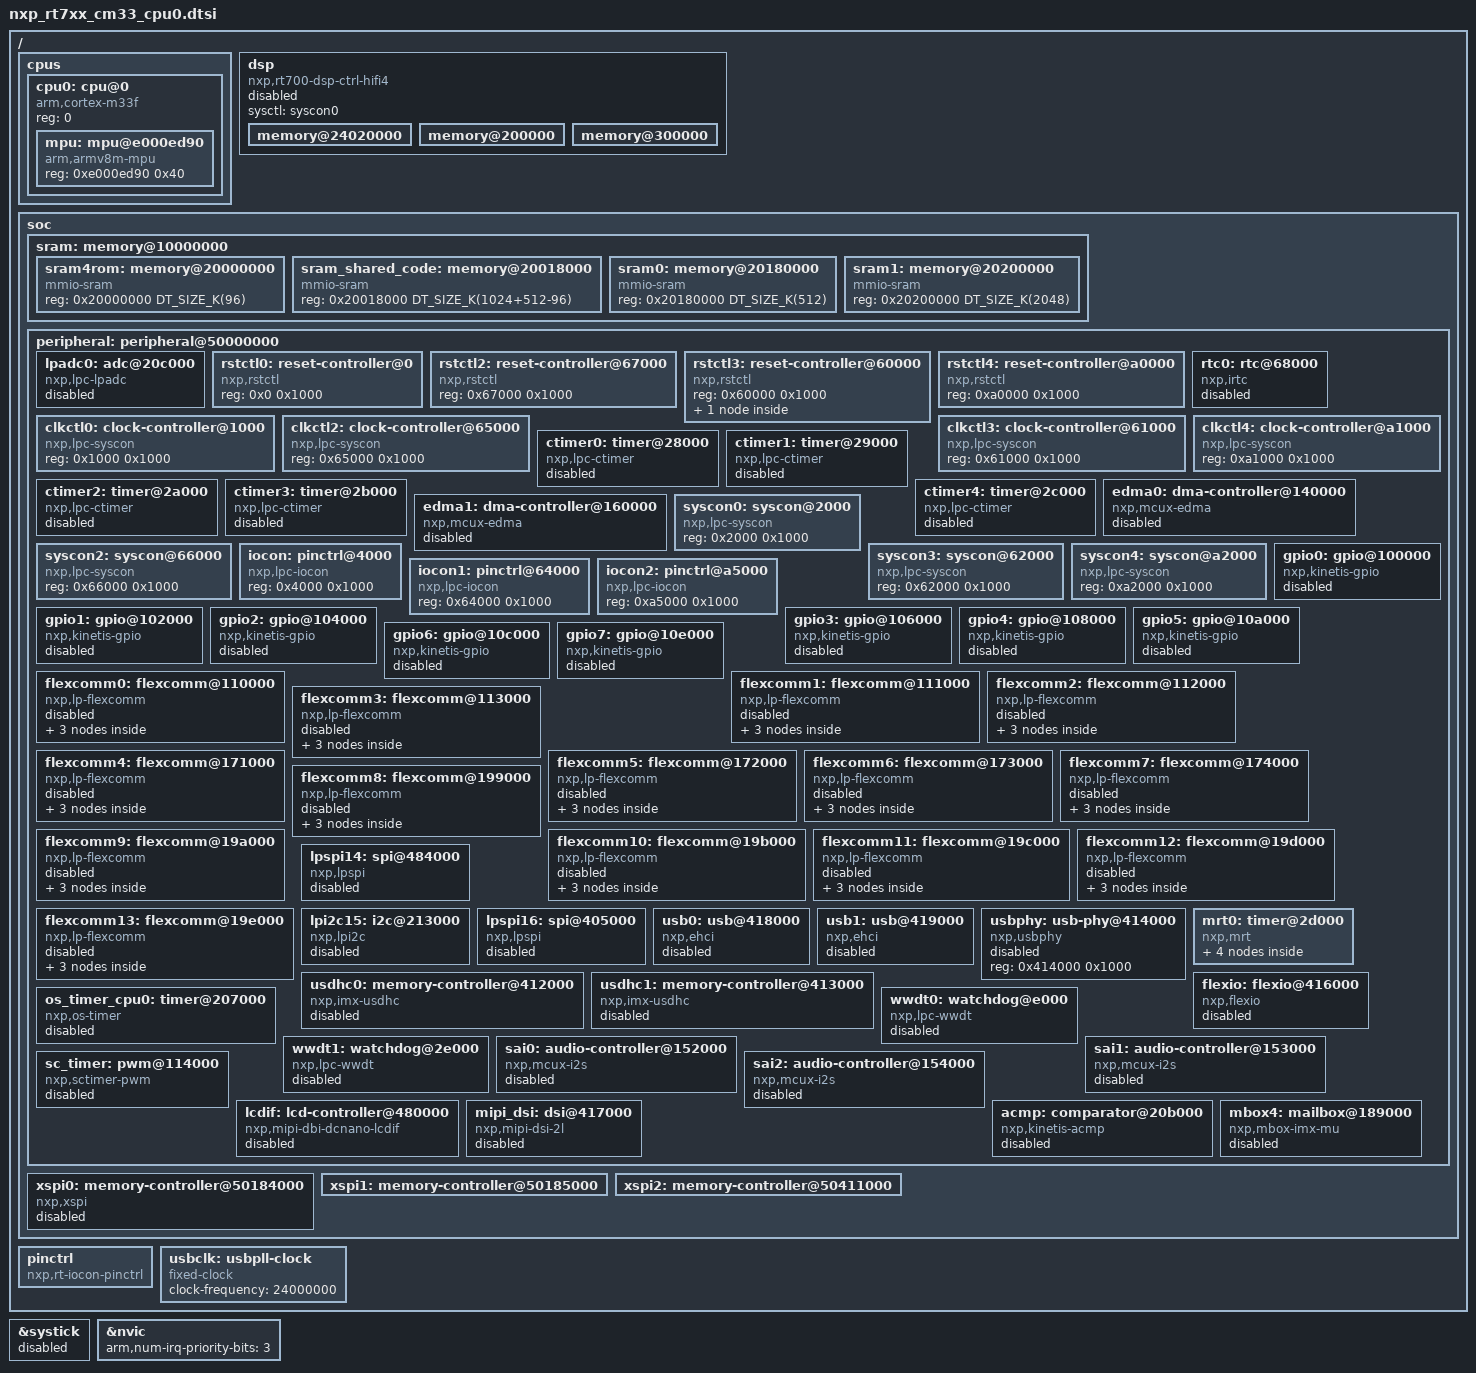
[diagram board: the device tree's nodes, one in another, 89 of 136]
/*
 * Copyright 2024-2025 NXP
 *
 * SPDX-License-Identifier: Apache-2.0
 */

#include <mem.h>
#include <arm/armv8-m.dtsi>
#include <zephyr/dt-bindings/adc/adc.h>
#include <zephyr/dt-bindings/clock/mcux_lpc_syscon_clock.h>
#include <zephyr/dt-bindings/gpio/gpio.h>
#include <zephyr/dt-bindings/mipi_dsi/mipi_dsi.h>
#include <zephyr/dt-bindings/memory-attr/memory-attr-arm.h>
#include <zephyr/dt-bindings/reset/nxp_syscon_reset_common.h>
#include <zephyr/dt-bindings/misc/nxp_rtxxx_dsp_ctrl.h>

/ {
	cpus {
		#address-cells = <1>;
		#size-cells = <0>;

		cpu0: cpu@0 {
			compatible = "arm,cortex-m33f";
			reg = <0>;
			#address-cells = <1>;
			#size-cells = <1>;

			mpu: mpu@e000ed90 {
				compatible = "arm,armv8m-mpu";
				reg = <0xe000ed90 0x40>;
			};
		};
	};

	dsp: dsp {
		#address-cells = <1>;
		#size-cells = <1>;

		compatible = "nxp,rt700-dsp-ctrl-hifi4";
		sysctl = <&syscon0>;

		status = "disabled";

		/* 1st 1 kiB of HiFi4's ITCM */
		memory@24020000 {
			reg = <0x24020000 DT_SIZE_K(1)>;
			type = <NXP_RTXXX_DSP_REGION_RESET>;
		};

		/* 1st half of reserved HiFi4 SRAM region (see below) */
		memory@200000 {
			reg = <0x200000 DT_SIZE_M(1)>;
			type = <NXP_RTXXX_DSP_REGION_TEXT>;
		};

		/* 2nd half of reserved HiFi4 SRAM region (see below) */
		memory@300000 {
			reg = <0x300000 DT_SIZE_M(1)>;
			type = <NXP_RTXXX_DSP_REGION_DATA>;
		};
	};

	soc {
		sram: memory@10000000 {
			ranges = <0x0 0x10000000 0x780000
				0x20000000 0x30000000 0x780000>;
		};

		peripheral: peripheral@50000000 {
			ranges = <0x0 0x50000000 0x10000000>;
		};

		xspi0: memory-controller@50184000 {
			reg = <0x50184000 0x1000>, <0x38000000 DT_SIZE_M(128)>;
		};

		xspi1: memory-controller@50185000 {
			reg = <0x50185000 0x1000>, <0x18000000 DT_SIZE_M(128)>;
		};

		xspi2: memory-controller@50411000 {
			reg = <0x50411000 0x1000>, <0x70000000 DT_SIZE_M(128)>;
		};

	};

	pinctrl: pinctrl {
		compatible = "nxp,rt-iocon-pinctrl";
	};

	/* USB PLL */
	usbclk: usbpll-clock {
		compatible = "fixed-clock";
		clock-frequency = <24000000>;
		#clock-cells = <0>;
	};
};


&sram {
	#address-cells = <1>;
	#size-cells = <1>;

	/* RT7XX SRAM partitions are shared between code and data. Boards can override
	 *  the reg properties of either sram0 or sram_code nodes to change the balance
	 *  of SRAM allocation.
	 *
	 * The SRAM region [0x000000-0x017FFF] is reserved for ROM bootloader execution.
	 * Can be reused after boot.
	 * The SRAM region [0x018000-0x17FFFF] is reserved for Non-cached shared memory
	 * or application data.
	 * The SRAM region [0x180000-0x1FFFFF] is reserved for CPU0 application, last
	 * 2MB non-cacheable data for NPU/GPU/Display etc.
	 * The SRAM region [0x200000-0x400000] is reserved for HiFi4 application.
	 */

	sram4rom: memory@20000000{
		compatible = "mmio-sram";
		reg = <0x20000000 DT_SIZE_K(96)>;
	};

	/* This partition is shared with code in RAM */
	sram_shared_code: memory@20018000{
		compatible = "mmio-sram";
		reg = <0x20018000 DT_SIZE_K(1024+512-96)>;
	};

	sram0: memory@20180000 {
		compatible = "mmio-sram";
		reg = <0x20180000 DT_SIZE_K(512)>;
	};

	sram1: memory@20200000 {
		compatible =  "mmio-sram";
		reg = <0x20200000 DT_SIZE_K(2048)>;
	};
};

&peripheral {
	#address-cells = <1>;
	#size-cells = <1>;
	/*
	 * Note that the offsets here are relative to the base address.
	 * The base addresses differ between non-secure (0x40000000)
	 * and secure modes (0x50000000).
	 */

	lpadc0: adc@20c000 {
		compatible = "nxp,lpc-lpadc";
		reg = <0x20c000 0x304>;
		interrupts = <15 0>;
		status = "disabled";
		clk-divider = <1>;
		clk-source = <0>;
		voltage-ref= <1>;
		calibration-average = <128>;
		power-level = <0>;
		offset-value-a = <10>;
		offset-value-b = <10>;
		#io-channel-cells = <1>;
		clocks = <&clkctl3 MCUX_LPADC1_CLK>;
	};

	rstctl0: reset-controller@0 {
		compatible = "nxp,rstctl";
		reg = <0x0 0x1000>;
		#reset-cells = <1>;
	};

	rstctl2: reset-controller@67000 {
		compatible = "nxp,rstctl";
		reg = <0x67000 0x1000>;
		#reset-cells = <1>;
	};

	rstctl3: reset-controller@60000 {
		compatible = "nxp,rstctl";
		reg = <0x60000 0x1000>;
		#reset-cells = <1>;
		#address-cells = <1>;
		#size-cells = <1>;

		sysrststat: hwinfo@60000 {
			compatible = "nxp,rstctl-hwinfo";
			reg = <0x60000 0x4>;
		};
	};

	rstctl4: reset-controller@a0000 {
		compatible = "nxp,rstctl";
		reg = <0xa0000 0x1000>;
		#reset-cells = <1>;
	};

	rtc0: rtc@68000 {
		compatible = "nxp,irtc";
		reg = <0x68000 0x1000>;
		interrupts = <26 0>, <27 0>;
		clock-frequency = <32768>;
		prescaler = <1>;
		alarms-count = <1>;
		status = "disabled";
	};

	clkctl0: clock-controller@1000 {
		compatible = "nxp,lpc-syscon";
		reg = <0x1000 0x1000>;
		#clock-cells = <1>;
	};

	clkctl2: clock-controller@65000 {
		compatible = "nxp,lpc-syscon";
		reg = <0x65000 0x1000>;
		#clock-cells = <1>;
	};

	clkctl3: clock-controller@61000 {
		compatible = "nxp,lpc-syscon";
		reg = <0x61000 0x1000>;
		#clock-cells = <1>;
	};

	clkctl4: clock-controller@a1000 {
		compatible = "nxp,lpc-syscon";
		reg = <0xa1000 0x1000>;
		#clock-cells = <1>;
	};

	ctimer0: timer@28000 {
		compatible = "nxp,lpc-ctimer";
		reg = <0x28000 0x1000>;
		interrupts = <3 0>;
		status = "disabled";
		clk-source = <1>;
		clocks = <&clkctl0 MCUX_CTIMER0_CLK>;
		mode = <0>;
		input = <0>;
		prescale = <0>;
	};

	ctimer1: timer@29000 {
		compatible = "nxp,lpc-ctimer";
		reg = <0x29000 0x1000>;
		interrupts = <4 0>;
		status = "disabled";
		clk-source = <1>;
		clocks = <&clkctl0 MCUX_CTIMER1_CLK>;
		mode = <0>;
		input = <0>;
		prescale = <0>;
	};

	ctimer2: timer@2a000 {
		compatible = "nxp,lpc-ctimer";
		reg = <0x2a000 0x1000>;
		interrupts = <32 0>;
		status = "disabled";
		clk-source = <1>;
		clocks = <&clkctl0 MCUX_CTIMER2_CLK>;
		mode = <0>;
		input = <0>;
		prescale = <0>;
	};

	ctimer3: timer@2b000 {
		compatible = "nxp,lpc-ctimer";
		reg = <0x2b000 0x1000>;
		interrupts = <6 0>;
		status = "disabled";
		clk-source = <1>;
		clocks = <&clkctl0 MCUX_CTIMER3_CLK>;
		mode = <0>;
		input = <0>;
		prescale = <0>;
	};

	ctimer4: timer@2c000 {
		compatible = "nxp,lpc-ctimer";
		reg = <0x2c000 0x1000>;
		interrupts = <33 0>;
		status = "disabled";
		clk-source = <1>;
		clocks = <&clkctl0 MCUX_CTIMER4_CLK>;
		mode = <0>;
		input = <0>;
		prescale = <0>;
	};

	edma0: dma-controller@140000 {
		#dma-cells = <2>;
		compatible = "nxp,mcux-edma";
		nxp,version = <4>;
		dma-channels = <16>;
		dma-requests = <105>;
		reg = <0x140000 0x1000>;
		interrupts = <59 0>, <60 0>, <61 0>, <62 0>,
			<63 0>, <64 0>, <65 0>, <66 0>,
			<67 0>, <68 0>, <69 0>, <70 0>,
			<71 0>, <72 0>, <73 0>, <74 0>;
		no-error-irq;
		status = "disabled";
	};

	edma1: dma-controller@160000 {
		#dma-cells = <2>;
		compatible = "nxp,mcux-edma";
		nxp,version = <4>;
		dma-channels = <16>;
		dma-requests = <105>;
		reg = <0x160000 0x1000>;
		interrupts = <75 0>, <76 0>, <77 0>, <78 0>,
			<79 0>, <80 0>, <81 0>, <82 0>,
			<83 0>, <84 0>, <85 0>, <86 0>,
			<87 0>, <88 0>, <89 0>, <90 0>;
		no-error-irq;
		status = "disabled";
	};

	syscon0: syscon@2000 {
		compatible = "nxp,lpc-syscon";
		reg = <0x2000 0x1000>;
		#clock-cells = <1>;
		#pinmux-cells = <2>;
	};

	syscon2: syscon@66000 {
		compatible = "nxp,lpc-syscon";
		reg = <0x66000 0x1000>;
		#clock-cells = <1>;
	};

	syscon3: syscon@62000 {
		compatible = "nxp,lpc-syscon";
		reg = <0x62000 0x1000>;
		#clock-cells = <1>;
	};

	syscon4: syscon@a2000 {
		compatible = "nxp,lpc-syscon";
		reg = <0xa2000 0x1000>;
		#clock-cells = <1>;
	};

	iocon: pinctrl@4000 {
		compatible = "nxp,lpc-iocon";
		reg = <0x4000 0x1000>;
		status = "okay";
	};

	iocon1: pinctrl@64000 {
		compatible = "nxp,lpc-iocon";
		reg = <0x64000 0x1000>;
		status = "okay";
	};

	iocon2: pinctrl@a5000 {
		compatible = "nxp,lpc-iocon";
		reg = <0xa5000 0x1000>;
		status = "okay";
	};

	gpio0: gpio@100000 {
		compatible = "nxp,kinetis-gpio";
		status = "disabled";
		reg = <0x100000 0x1000>;
		interrupts = <91 0>,<92 0>;
		gpio-controller;
		#gpio-cells = <2>;
		nxp,kinetis-port = <&gpio0>;
	};

	gpio1: gpio@102000 {
		compatible = "nxp,kinetis-gpio";
		status = "disabled";
		reg = <0x102000 0x1000>;
		interrupts = <93 0>,<94 0>;
		gpio-controller;
		#gpio-cells = <2>;
		nxp,kinetis-port = <&gpio1>;
	};

	gpio2: gpio@104000 {
		compatible = "nxp,kinetis-gpio";
		status = "disabled";
		reg = <0x104000 0x1000>;
		interrupts = <95 0>,<96 0>;
		gpio-controller;
		#gpio-cells = <2>;
		nxp,kinetis-port = <&gpio2>;
	};

	gpio3: gpio@106000 {
		compatible = "nxp,kinetis-gpio";
		status = "disabled";
		reg = <0x106000 0x1000>;
		interrupts = <97 0>,<98 0>;
		gpio-controller;
		#gpio-cells = <2>;
		nxp,kinetis-port = <&gpio3>;
	};

	gpio4: gpio@108000 {
		compatible = "nxp,kinetis-gpio";
		status = "disabled";
		reg = <0x108000 0x1000>;
		interrupts = <99 0>,<100 0>;
		gpio-controller;
		#gpio-cells = <2>;
		nxp,kinetis-port = <&gpio4>;
	};

	gpio5: gpio@10a000 {
		compatible = "nxp,kinetis-gpio";
		status = "disabled";
		reg = <0x10a000 0x1000>;
		interrupts = <101 0>,<102 0>;
		gpio-controller;
		#gpio-cells = <2>;
		nxp,kinetis-port = <&gpio5>;
	};

	gpio6: gpio@10c000 {
		compatible = "nxp,kinetis-gpio";
		status = "disabled";
		reg = <0x10c000 0x1000>;
		interrupts = <103 0>,<104 0>;
		gpio-controller;
		#gpio-cells = <2>;
		nxp,kinetis-port = <&gpio6>;
	};

	gpio7: gpio@10e000 {
		compatible = "nxp,kinetis-gpio";
		status = "disabled";
		reg = <0x10e000 0x1000>;
		interrupts = <105 0>,<106 0>;
		gpio-controller;
		#gpio-cells = <2>;
		nxp,kinetis-port = <&gpio7>;
	};

	flexcomm0: flexcomm@110000 {
		compatible = "nxp,lp-flexcomm";
		reg = <0x110000 0x1000>;
		interrupts = <7 0>;
		status = "disabled";

		/* Empty ranges property implies parent and child address space is identical */
		ranges = <>;
		#address-cells = <1>;
		#size-cells = <1>;

		flexcomm0_lpuart0: serial@110000 {
			compatible = "nxp,lpuart";
			reg = <0x110000 0x1000>;
			clocks = <&clkctl0 MCUX_FLEXCOMM0_CLK>;
			status = "disabled";
		};

		flexcomm0_lpspi0: spi@110000 {
			compatible = "nxp,lpspi";
			reg = <0x110000 0x1000>;
			clocks = <&clkctl0 MCUX_FLEXCOMM0_CLK>;
			#address-cells = <1>;
			#size-cells = <0>;
			tx-fifo-size = <8>;
			rx-fifo-size = <8>;
			status = "disabled";
		};

		flexcomm0_lpi2c0: i2c@110800 {
			compatible = "nxp,lpi2c";
			reg = <0x110800 0x1000>;
			clocks = <&clkctl0 MCUX_FLEXCOMM0_CLK>;
			#address-cells = <1>;
			#size-cells = <0>;
			status = "disabled";
		};
	};

	flexcomm1: flexcomm@111000 {
		compatible = "nxp,lp-flexcomm";
		reg = <0x111000 0x1000>;
		interrupts = <8 0>;
		status = "disabled";

		/* Empty ranges property implies parent and child address space is identical */
		ranges = <>;
		#address-cells = <1>;
		#size-cells = <1>;

		flexcomm1_lpuart1: serial@111000 {
			compatible = "nxp,lpuart";
			reg = <0x111000 0x1000>;
			clocks = <&clkctl0 MCUX_FLEXCOMM1_CLK>;
			status = "disabled";
		};

		flexcomm1_lpspi1: spi@111000 {
			compatible = "nxp,lpspi";
			reg = <0x111000 0x1000>;
			clocks = <&clkctl0 MCUX_FLEXCOMM1_CLK>;
			#address-cells = <1>;
			#size-cells = <0>;
			tx-fifo-size = <8>;
			rx-fifo-size = <8>;
			status = "disabled";
		};

		flexcomm1_lpi2c1: i2c@111800 {
			compatible = "nxp,lpi2c";
			reg = <0x111800 0x1000>;
			clocks = <&clkctl0 MCUX_FLEXCOMM1_CLK>;
			#address-cells = <1>;
			#size-cells = <0>;
			status = "disabled";
		};
	};

	flexcomm2: flexcomm@112000 {
		compatible = "nxp,lp-flexcomm";
		reg = <0x112000 0x1000>;
		interrupts = <9 0>;
		status = "disabled";

		/* Empty ranges property implies parent and child address space is identical */
		ranges = <>;
		#address-cells = <1>;
		#size-cells = <1>;

		flexcomm2_lpuart2: serial@112000 {
			compatible = "nxp,lpuart";
			reg = <0x112000 0x1000>;
			clocks = <&clkctl0 MCUX_FLEXCOMM2_CLK>;
			status = "disabled";
		};

		flexcomm2_lpspi2: spi@112000 {
			compatible = "nxp,lpspi";
			reg = <0x112000 0x1000>;
			clocks = <&clkctl0 MCUX_FLEXCOMM2_CLK>;
			#address-cells = <1>;
			#size-cells = <0>;
			tx-fifo-size = <8>;
			rx-fifo-size = <8>;
			status = "disabled";
		};

		flexcomm2_lpi2c2: i2c@112800 {
			compatible = "nxp,lpi2c";
			reg = <0x112800 0x1000>;
			clocks = <&clkctl0 MCUX_FLEXCOMM2_CLK>;
			#address-cells = <1>;
			#size-cells = <0>;
			status = "disabled";
		};
	};

	flexcomm3: flexcomm@113000 {
		compatible = "nxp,lp-flexcomm";
		reg = <0x113000 0x1000>;
		interrupts = <10 0>;
		status = "disabled";

		/* Empty ranges property implies parent and child address space is identical */
		ranges = <>;
		#address-cells = <1>;
		#size-cells = <1>;

		flexcomm3_lpuart3: serial@113000 {
			compatible = "nxp,lpuart";
			reg = <0x113000 0x1000>;
			clocks = <&clkctl0 MCUX_FLEXCOMM3_CLK>;
			status = "disabled";
		};

		flexcomm3_lpspi3: spi@113000 {
			compatible = "nxp,lpspi";
			reg = <0x113000 0x1000>;
			clocks = <&clkctl0 MCUX_FLEXCOMM3_CLK>;
			#address-cells = <1>;
			#size-cells = <0>;
			tx-fifo-size = <8>;
			rx-fifo-size = <8>;
			status = "disabled";
		};

		flexcomm3_lpi2c3: i2c@113800 {
			compatible = "nxp,lpi2c";
			reg = <0x113800 0x1000>;
			clocks = <&clkctl0 MCUX_FLEXCOMM3_CLK>;
			#address-cells = <1>;
			#size-cells = <0>;
			status = "disabled";
		};
	};

	flexcomm4: flexcomm@171000 {
		compatible = "nxp,lp-flexcomm";
		reg = <0x171000 0x1000>;
		interrupts = <11 0>;
		status = "disabled";

		/* Empty ranges property implies parent and child address space is identical */
		ranges = <>;
		#address-cells = <1>;
		#size-cells = <1>;

		flexcomm4_lpuart4: serial@171000 {
			compatible = "nxp,lpuart";
			reg = <0x171000 0x1000>;
			clocks = <&clkctl0 MCUX_FLEXCOMM4_CLK>;
			status = "disabled";
		};

		flexcomm4_lpspi4: spi@171000 {
			compatible = "nxp,lpspi";
			reg = <0x171000 0x1000>;
			clocks = <&clkctl0 MCUX_FLEXCOMM4_CLK>;
			#address-cells = <1>;
			#size-cells = <0>;
			tx-fifo-size = <8>;
			rx-fifo-size = <8>;
			status = "disabled";
		};

		flexcomm4_lpi2c4: i2c@171800 {
			compatible = "nxp,lpi2c";
			reg = <0x171800 0x1000>;
			clocks = <&clkctl0 MCUX_FLEXCOMM4_CLK>;
			#address-cells = <1>;
			#size-cells = <0>;
			status = "disabled";
		};
	};

	flexcomm5: flexcomm@172000 {
		compatible = "nxp,lp-flexcomm";
		reg = <0x172000 0x1000>;
		interrupts = <12 0>;
		status = "disabled";

		/* Empty ranges property implies parent and child address space is identical */
		ranges = <>;
		#address-cells = <1>;
		#size-cells = <1>;

		flexcomm5_lpuart5: serial@172000 {
			compatible = "nxp,lpuart";
			reg = <0x172000 0x1000>;
			clocks = <&clkctl0 MCUX_FLEXCOMM5_CLK>;
			status = "disabled";
		};

		flexcomm5_lpspi5: spi@172000 {
			compatible = "nxp,lpspi";
			reg = <0x172000 0x1000>;
			clocks = <&clkctl0 MCUX_FLEXCOMM5_CLK>;
			#address-cells = <1>;
			#size-cells = <0>;
			tx-fifo-size = <8>;
			rx-fifo-size = <8>;
			status = "disabled";
		};

		flexcomm5_lpi2c5: i2c@172800 {
			compatible = "nxp,lpi2c";
			reg = <0x172800 0x1000>;
			clocks = <&clkctl0 MCUX_FLEXCOMM5_CLK>;
			#address-cells = <1>;
			#size-cells = <0>;
			status = "disabled";
		};
	};

	flexcomm6: flexcomm@173000 {
		compatible = "nxp,lp-flexcomm";
		reg = <0x173000 0x1000>;
		interrupts = <35 0>;
		status = "disabled";

		/* Empty ranges property implies parent and child address space is identical */
		ranges = <>;
		#address-cells = <1>;
		#size-cells = <1>;

		flexcomm6_lpuart6: serial@173000 {
			compatible = "nxp,lpuart";
			reg = <0x173000 0x1000>;
			clocks = <&clkctl0 MCUX_FLEXCOMM6_CLK>;
			status = "disabled";
		};

		flexcomm6_lpspi6: spi@173000 {
			compatible = "nxp,lpspi";
			reg = <0x173000 0x1000>;
			clocks = <&clkctl0 MCUX_FLEXCOMM6_CLK>;
			#address-cells = <1>;
			#size-cells = <0>;
			tx-fifo-size = <8>;
			rx-fifo-size = <8>;
			status = "disabled";
		};

		flexcomm6_lpi2c6: i2c@173800 {
			compatible = "nxp,lpi2c";
			reg = <0x173800 0x1000>;
			clocks = <&clkctl0 MCUX_FLEXCOMM6_CLK>;
			#address-cells = <1>;
			#size-cells = <0>;
			status = "disabled";
		};
	};

	flexcomm7: flexcomm@174000 {
		compatible = "nxp,lp-flexcomm";
		reg = <0x174000 0x1000>;
		interrupts = <36 0>;
		status = "disabled";

		/* Empty ranges property implies parent and child address space is identical */
		ranges = <>;
		#address-cells = <1>;
		#size-cells = <1>;

		flexcomm7_lpuart7: serial@174000 {
			compatible = "nxp,lpuart";
			reg = <0x174000 0x1000>;
			clocks = <&clkctl0 MCUX_FLEXCOMM7_CLK>;
			status = "disabled";
		};

		flexcomm7_lpspi7: spi@174000 {
			compatible = "nxp,lpspi";
			reg = <0x174000 0x1000>;
			clocks = <&clkctl0 MCUX_FLEXCOMM7_CLK>;
			#address-cells = <1>;
			#size-cells = <0>;
			tx-fifo-size = <8>;
			rx-fifo-size = <8>;
			status = "disabled";
		};

		flexcomm7_lpi2c7: i2c@174800 {
			compatible = "nxp,lpi2c";
			reg = <0x174800 0x1000>;
			clocks = <&clkctl0 MCUX_FLEXCOMM7_CLK>;
			#address-cells = <1>;
			#size-cells = <0>;
			status = "disabled";
		};
	};

	flexcomm8: flexcomm@199000 {
		compatible = "nxp,lp-flexcomm";
		reg = <0x199000 0x1000>;
		interrupts = <47 0>;
		status = "disabled";

		/* Empty ranges property implies parent and child address space is identical */
		ranges = <>;
		#address-cells = <1>;
		#size-cells = <1>;

		flexcomm8_lpuart8: serial@199000 {
			compatible = "nxp,lpuart";
			reg = <0x199000 0x1000>;
			clocks = <&clkctl0 MCUX_FLEXCOMM8_CLK>;
			status = "disabled";
		};

		flexcomm8_lpspi8: spi@199000 {
			compatible = "nxp,lpspi";
			reg = <0x199000 0x1000>;
			clocks = <&clkctl0 MCUX_FLEXCOMM8_CLK>;
			#address-cells = <1>;
			#size-cells = <0>;
			tx-fifo-size = <8>;
			rx-fifo-size = <8>;
			status = "disabled";
		};

		flexcomm8_lpi2c8: i2c@199800 {
			compatible = "nxp,lpi2c";
			reg = <0x199800 0x1000>;
			clocks = <&clkctl0 MCUX_FLEXCOMM8_CLK>;
			#address-cells = <1>;
			#size-cells = <0>;
			status = "disabled";
		};
	};

	flexcomm9: flexcomm@19a000 {
		compatible = "nxp,lp-flexcomm";
		reg = <0x19a000 0x1000>;
		interrupts = <48 0>;
		status = "disabled";

		/* Empty ranges property implies parent and child address space is identical */
		ranges = <>;
		#address-cells = <1>;
		#size-cells = <1>;

		flexcomm9_lpuart9: serial@19a000 {
			compatible = "nxp,lpuart";
			reg = <0x19a000 0x1000>;
			clocks = <&clkctl0 MCUX_FLEXCOMM9_CLK>;
			status = "disabled";
		};

		flexcomm9_lpspi9: spi@19a000 {
			compatible = "nxp,lpspi";
			reg = <0x19a000 0x1000>;
			clocks = <&clkctl0 MCUX_FLEXCOMM9_CLK>;
			#address-cells = <1>;
			#size-cells = <0>;
			tx-fifo-size = <8>;
			rx-fifo-size = <8>;
			status = "disabled";
		};

		flexcomm9_lpi2c9: i2c@19a800 {
			compatible = "nxp,lpi2c";
			reg = <0x19a800 0x1000>;
			clocks = <&clkctl0 MCUX_FLEXCOMM9_CLK>;
			#address-cells = <1>;
			#size-cells = <0>;
			status = "disabled";
		};
	};

	flexcomm10: flexcomm@19b000 {
		compatible = "nxp,lp-flexcomm";
		reg = <0x19b000 0x1000>;
		interrupts = <49 0>;
		status = "disabled";

		/* Empty ranges property implies parent and child address space is identical */
		ranges = <>;
		#address-cells = <1>;
		#size-cells = <1>;

		flexcomm10_lpuart10: serial@19b000 {
			compatible = "nxp,lpuart";
			reg = <0x19b000 0x1000>;
			clocks = <&clkctl0 MCUX_FLEXCOMM10_CLK>;
			status = "disabled";
		};

		flexcomm10_lpspi10: spi@19b000 {
			compatible = "nxp,lpspi";
			reg = <0x19b000 0x1000>;
			clocks = <&clkctl0 MCUX_FLEXCOMM10_CLK>;
			#address-cells = <1>;
			#size-cells = <0>;
			tx-fifo-size = <8>;
			rx-fifo-size = <8>;
			status = "disabled";
		};

		flexcomm10_lpi2c10: i2c@19b800 {
			compatible = "nxp,lpi2c";
			reg = <0x19b800 0x1000>;
			clocks = <&clkctl0 MCUX_FLEXCOMM10_CLK>;
			#address-cells = <1>;
			#size-cells = <0>;
			status = "disabled";
		};
	};

	flexcomm11: flexcomm@19c000 {
		compatible = "nxp,lp-flexcomm";
		reg = <0x19c000 0x1000>;
		interrupts = <50 0>;
		status = "disabled";

		/* Empty ranges property implies parent and child address space is identical */
		ranges = <>;
		#address-cells = <1>;
		#size-cells = <1>;

		flexcomm11_lpuart11: serial@19c000 {
			compatible = "nxp,lpuart";
			reg = <0x19c000 0x1000>;
			clocks = <&clkctl0 MCUX_FLEXCOMM11_CLK>;
			status = "disabled";
		};

		flexcomm11_lpspi11: spi@19c000 {
			compatible = "nxp,lpspi";
			reg = <0x19c000 0x1000>;
			clocks = <&clkctl0 MCUX_FLEXCOMM11_CLK>;
			#address-cells = <1>;
			#size-cells = <0>;
			tx-fifo-size = <8>;
			rx-fifo-size = <8>;
			status = "disabled";
		};

		flexcomm11_lpi2c11: i2c@19c800 {
			compatible = "nxp,lpi2c";
			reg = <0x19c800 0x1000>;
			clocks = <&clkctl0 MCUX_FLEXCOMM11_CLK>;
			#address-cells = <1>;
			#size-cells = <0>;
			status = "disabled";
		};
	};

	flexcomm12: flexcomm@19d000 {
		compatible = "nxp,lp-flexcomm";
		reg = <0x19d000 0x1000>;
		interrupts = <51 0>;
		status = "disabled";

		/* Empty ranges property implies parent and child address space is identical */
		ranges = <>;
		#address-cells = <1>;
		#size-cells = <1>;

		flexcomm12_lpuart12: serial@19d000 {
			compatible = "nxp,lpuart";
			reg = <0x19d000 0x1000>;
			clocks = <&clkctl0 MCUX_FLEXCOMM12_CLK>;
			status = "disabled";
		};

		flexcomm12_lpspi12: spi@19d000 {
			compatible = "nxp,lpspi";
			reg = <0x19d000 0x1000>;
			clocks = <&clkctl0 MCUX_FLEXCOMM12_CLK>;
			#address-cells = <1>;
			#size-cells = <0>;
			tx-fifo-size = <8>;
			rx-fifo-size = <8>;
			status = "disabled";
		};

		flexcomm12_lpi2c12: i2c@19d800 {
			compatible = "nxp,lpi2c";
			reg = <0x19d800 0x1000>;
			clocks = <&clkctl0 MCUX_FLEXCOMM12_CLK>;
			#address-cells = <1>;
			#size-cells = <0>;
			status = "disabled";
		};
	};

	flexcomm13: flexcomm@19e000 {
		compatible = "nxp,lp-flexcomm";
		reg = <0x19e000 0x1000>;
		interrupts = <52 0>;
		status = "disabled";

		/* Empty ranges property implies parent and child address space is identical */
		ranges = <>;
		#address-cells = <1>;
		#size-cells = <1>;

		flexcomm13_lpuart13: serial@19e000 {
			compatible = "nxp,lpuart";
			reg = <0x19e000 0x1000>;
			clocks = <&clkctl0 MCUX_FLEXCOMM13_CLK>;
			status = "disabled";
		};

		flexcomm13_lpspi13: spi@19e000 {
			compatible = "nxp,lpspi";
			reg = <0x19e000 0x1000>;
			clocks = <&clkctl0 MCUX_FLEXCOMM13_CLK>;
			#address-cells = <1>;
			#size-cells = <0>;
			tx-fifo-size = <8>;
			rx-fifo-size = <8>;
			status = "disabled";
		};

		flexcomm13_lpi2c13: i2c@19e800 {
			compatible = "nxp,lpi2c";
			reg = <0x19e800 0x1000>;
			clocks = <&clkctl0 MCUX_FLEXCOMM13_CLK>;
			#address-cells = <1>;
			#size-cells = <0>;
			status = "disabled";
		};
	};

	/* LPFlexcomm14/16 only support LPSPI function  */
	lpspi14: spi@484000 {
		compatible = "nxp,lpspi";
		reg = <0x484000 0x1000>;
		interrupts = <13 0>;
		clocks = <&clkctl4 MCUX_LPSPI14_CLK>;
		#address-cells = <1>;
		#size-cells = <0>;
		tx-fifo-size = <8>;
		rx-fifo-size = <8>;
		status = "disabled";
	};


	/* LPFlexcomm15 only support LPI2C function. */
	lpi2c15: i2c@213000 {
		compatible = "nxp,lpi2c";
		reg = <0x213000 0x1000>;
		interrupts = <14 0>;
		#address-cells = <1>;
		#size-cells = <0>;
		clocks = <&clkctl4 MCUX_LPI2C15_CLK>;
		status = "disabled";
	};

	/* LPFlexcomm14/16 only support LPSPI function  */
	lpspi16: spi@405000 {
		compatible = "nxp,lpspi";
		reg = <0x405000 0x1000>;
		interrupts = <53 0>;
		clocks = <&clkctl4 MCUX_LPSPI16_CLK>;
		#address-cells = <1>;
		#size-cells = <0>;
		tx-fifo-size = <8>;
		rx-fifo-size = <8>;
		status = "disabled";
	};

	usb0: usb@418000 {
		compatible = "nxp,ehci";
		reg = <0x418000 0x1000>;
		interrupts = <40 0>;
		interrupt-names = "usb_otg";
		clocks = <&usbclk>;
		num-bidir-endpoints = <8>;
		status = "disabled";
	};

	usb1: usb@419000 {
		compatible = "nxp,ehci";
		reg = <0x419000 0x1000>;
		interrupts = <41 0>;
		interrupt-names = "usb_otg";
		clocks = <&usbclk>;
		num-bidir-endpoints = <8>;
		status = "disabled";
	};

	usbphy: usb-phy@414000 {
		compatible = "nxp,usbphy";
		reg = <0x414000 0x1000>;
		status = "disabled";
	};

	usdhc0: memory-controller@412000 {
		compatible = "nxp,imx-usdhc";
		reg = <0x412000 0x1000>;
		status = "disabled";
		interrupts = <37 0>;
		clocks = <&clkctl4 MCUX_USDHC1_CLK>;
		max-current-330 = <1020>;
		max-current-180 = <1020>;
		max-bus-freq = <208000000>;
		min-bus-freq = <400000>;
	};

	usdhc1: memory-controller@413000 {
		compatible = "nxp,imx-usdhc";
		reg = <0x413000 0x1000>;
		status = "disabled";
		interrupts = <38 0>;
		clocks = <&clkctl4 MCUX_USDHC2_CLK>;
		max-current-330 = <1020>;
		max-current-180 = <1020>;
		max-bus-freq = <208000000>;
		min-bus-freq = <400000>;
	};

	mrt0: timer@2d000 {
		compatible = "nxp,mrt";
		reg = <0x2d000 0x100>;
		interrupts = <2 0>;
		num-channels = <4>;
		num-bits = <24>;
		clocks = <&clkctl2 MCUX_MRT_CLK>;
		resets = <&rstctl0 NXP_SYSCON_RESET(3, 26)>;
		#address-cells = <1>;
		#size-cells = <0>;

		mrt0_channel0: mrt_channel@0 {
			compatible = "nxp,mrt-channel";
			reg = <0>;
			status = "disabled";
		};

		mrt0_channel1: mrt_channel@1 {
			compatible = "nxp,mrt-channel";
			reg = <1>;
			status = "disabled";
		};

		mrt0_channel2: mrt_channel@2 {
			compatible = "nxp,mrt-channel";
			reg = <2>;
			status = "disabled";
		};

		mrt0_channel3: mrt_channel@3 {
			compatible = "nxp,mrt-channel";
			reg = <3>;
			status = "disabled";
		};
	};

	flexio: flexio@416000 {
		compatible = "nxp,flexio";
		reg = <0x416000 0x1000>;
		status = "disabled";
		interrupts = <55 0>;
		clocks = <&clkctl4 MCUX_FLEXIO0_CLK>;
	};

	os_timer_cpu0: timer@207000 {
		compatible = "nxp,os-timer";
		reg = <0x207000 0x1000>;
		interrupts = <34 0>;
		status = "disabled";
	};

	wwdt0: watchdog@e000 {
		compatible = "nxp,lpc-wwdt";
		reg = <0xe000 0x1000>;
		interrupts = <42 0>;
		status = "disabled";
		clk-divider = <1>;
	};

	wwdt1: watchdog@2e000 {
		compatible = "nxp,lpc-wwdt";
		reg = <0x2e000 0x1000>;
		interrupts = <43 0>;
		status = "disabled";
		clk-divider = <1>;
	};

	sai0: audio-controller@152000 {
		compatible = "nxp,mcux-i2s";
		#address-cells = <1>;
		#size-cells = <0>;
		#pinmux-cells = <2>;
		reg = < 0x152000 0x1000>;
		clocks = <&clkctl0 MCUX_SAI0_CLK>;
		pinmuxes = <&syscon0 0x240 0x1>;
		interrupts = <115 0>;
		dmas = <&edma0 0 81>, <&edma0 1 82>;
		dma-names = "rx", "tx";
		nxp,tx-channel = <1>;
		nxp,tx-dma-channel = <1>;
		nxp,rx-dma-channel = <0>;
		status = "disabled";
	};

	sai1: audio-controller@153000 {
		compatible = "nxp,mcux-i2s";
		#address-cells = <1>;
		#size-cells = <0>;
		#pinmux-cells = <2>;
		reg = < 0x153000 0x1000>;
		clocks = <&clkctl0 MCUX_SAI1_CLK>;
		pinmuxes = <&syscon0 0x240 0x1>;
		interrupts = <116 0>;
		dmas = <&edma0 0 83>, <&edma0 0 84>;
		dma-names = "rx", "tx";
		nxp,tx-channel = <1>;
		nxp,tx-dma-channel = <2>;
		nxp,rx-dma-channel = <3>;
		status = "disabled";
	};

	sai2: audio-controller@154000 {
		compatible = "nxp,mcux-i2s";
		#address-cells = <1>;
		#size-cells = <0>;
		#pinmux-cells = <2>;
		reg = < 0x154000 0x1000>;
		clocks = <&clkctl0 MCUX_SAI2_CLK>;
		pinmuxes = <&syscon0 0x240 0x1>;
		interrupts = <117 0>;
		dmas = <&edma0 0 85>, <&edma0 0 86>;
		dma-names = "rx", "tx";
		nxp,tx-channel = <1>;
		nxp,tx-dma-channel = <2>;
		nxp,rx-dma-channel = <3>;
		status = "disabled";
	};

	sc_timer: pwm@114000 {
		compatible = "nxp,sctimer-pwm";
		reg = <0x114000 0x1000>;
		interrupts = <5 0>;
		status = "disabled";
		clocks = <&clkctl0 MCUX_SCTIMER_CLK>;
		prescaler = <8>;
		#pwm-cells = <3>;
	};

	lcdif: lcd-controller@480000 {
		compatible = "nxp,mipi-dbi-dcnano-lcdif";
		reg = <0x480000 0x1000>;
		interrupts = <56 0>;
		status = "disabled";
	};

	mipi_dsi: dsi@417000 {
		compatible = "nxp,mipi-dsi-2l";
		#address-cells = <1>;
		#size-cells = <0>;
		reg = <0x417000 0x1000>;
		interrupts = <58 0>;
		clocks = <&clkctl4 MCUX_MIPI_DSI_DPHY_CLK>,
				 <&clkctl4 MCUX_MIPI_DSI_ESC_CLK>,
				 <&clkctl4 MCUX_LCDIF_PIXEL_CLK>;
		clock-names = "dphy", "esc", "pixel";
		ulps-control;
		status = "disabled";
	};

	acmp: comparator@20b000 {
		compatible = "nxp,kinetis-acmp";
		reg = <0x20b000 0x1000>;
		interrupts = <17 0>;
		status = "disabled";
	};

	mbox4: mailbox@189000 {
		#mbox-cells = <1>;

		compatible = "nxp,mbox-imx-mu";
		reg = <0x189000 0x1000>;

		interrupts = <31 0>;
		rx-channels = <4>;

		status = "disabled";
	};
};

&systick {
	/*
	 * RT700 cm33_cpu0 relies by default on the OS Timer for system
	 * clock implementation, so the SysTick node is not to be enabled.
	 */
	status = "disabled";
};

&xspi0 {
	compatible = "nxp,xspi";
	status = "disabled";
	interrupts = <42 0>;
	#address-cells = <1>;
	#size-cells = <0>;
	clocks = <&clkctl0 MCUX_XSPI_CLK>;
};

&nvic {
	arm,num-irq-priority-bits = <3>;
};
